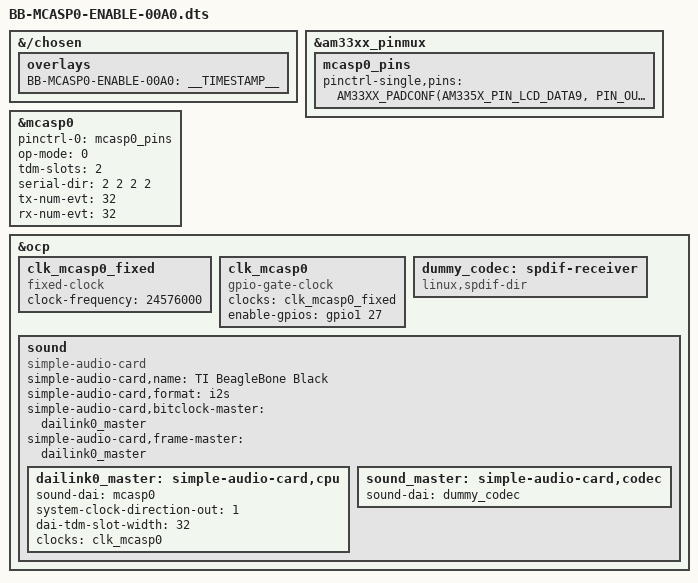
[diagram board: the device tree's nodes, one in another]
// SPDX-License-Identifier: GPL-2.0-only
/*
 * Copyright (C) 2012 Texas Instruments Incorporated - https://www.ti.com/
 */

/dts-v1/;
/plugin/;

#include <dt-bindings/pinctrl/am33xx.h>

/*
* Helper to show loaded overlays under: /proc/device-tree/chosen/overlays/
*/
&{/chosen} {
    overlays {
        BB-MCASP0-ENABLE-00A0 = __TIMESTAMP__;
    };
};

&am33xx_pinmux {
	mcasp0_pins: mcasp0_pins {
		/*

MCASP0
	AHCLKR - *Not needed, internal only*
	ACLKR
		X GPMC_BE1N - GPIO1_28 (P9)
		X MII...
		LCD_DATA12 (P8_35)
		X MCASP0_ACLKR - GPIO0_7/GPIO3_18 (P9)
	FSX
		LCD_DATA9 (P8_38)
	FSR
		X GPMC_CLK
		X MII1...
		X LCD_DATA13 (P8_33)
		X MCASP0_FSR - GPIO3_19 (P9)
	AXR0
		X GPMC...
		X MII...
		LCD_DATA10 (P8)
		X MCASP0_AXR0 - SPI1_D1 (P9)
		X MCASP0_AXR1 - GPIO3_20 (0 ohm to CLKOUT2) (P9)
	AXR1
		X GPMC_A11 (OE for HDMICLK, unusable)
		X MII...
		LCD_DATA14 (P8)
		X MCASP_AHCLKX - GPIO3_21 (P9_25)
		X MCASP0_AXR1 - GPIO3_20 (0 ohm to CLKOUT2) (P9)
	AXR2
		X MII...
		LCD_DATA11 (P8)
		X LCD_DATA12 (P8)
		X MCASP0_AHCLKR - SPI1_CS0 (P9)
		X MCASP0_ACLKR - GPIO0_7/GPIO3_18 (P9)
	AXR3
		X MII...
		LCD_DATA13 (P8)
		X LCD_DATA14 (P8)
		X MCASP0_AHCLKR - SPI1_CS0 (P9)
		X MCASP0_FSR - GPIO3_19 (P9_27)

	Can't get all 7 channels on LCD pins on P8, even w/o AHCLKR
	SPI1 used for iCE40 flashing
	Can't get all 7 channels on P9 either... Best bet is LCD on P8 + P3_19
	Note that GPIO3_19/P9_27 is BB_IRQ_ARM_TO_FPGA which we don't use on the FPGA

	LCD_DATA9 contains FSX though, we could use that instead of FSR...

	ACLKR: 	P8_35	Purple
	FSX: 	P8_38	Grey
	AXR0:	P8_36	Yellow
	AXR1:	P8_31	Orange
	AXR2:	P8_34	Blue
	AXR3:	P8_33	Green

		*/
		pinctrl-single,pins = <
			AM33XX_PADCONF(AM335X_PIN_LCD_DATA9, PIN_OUTPUT_PULLDOWN, MUX_MODE3) /* lcd_data9.mcasp0_fsx */
			AM33XX_PADCONF(AM335X_PIN_LCD_DATA10, PIN_INPUT_PULLUP, MUX_MODE3) /* lcd_data10.mcasp0_axr0 */
			AM33XX_PADCONF(AM335X_PIN_LCD_DATA11, PIN_INPUT_PULLUP, MUX_MODE4) /* lcd_data11.mcasp0_axr2 */
			AM33XX_PADCONF(AM335X_PIN_LCD_DATA12, PIN_OUTPUT_PULLDOWN, MUX_MODE3) /* lcd_data12.mcasp0_aclkr */
			AM33XX_PADCONF(AM335X_PIN_LCD_DATA13, PIN_INPUT_PULLUP, MUX_MODE4) /* lcd_data13.mcasp0_axr3 */
			AM33XX_PADCONF(AM335X_PIN_LCD_DATA14, PIN_INPUT_PULLUP, MUX_MODE3) /* lcd_data14.mcasp0_axr1 */
		>;
	};
};

&mcasp0	{
	#sound-dai-cells = <0>;
	pinctrl-names = "default";
	pinctrl-0 = <&mcasp0_pins>;
	status = "okay";
	op-mode = <0>;	/* MCASP_IIS_MODE */
	tdm-slots = <2>;
	serial-dir = <	/* 0: INACTIVE, 1: TX, 2: RX */
			2 2 2 2
		>;
	tx-num-evt = <32>;
	rx-num-evt = <32>;
};

&ocp {
	/* Use external clock as it can be divided into many more supported sample rates */
	clk_mcasp0_fixed: clk_mcasp0_fixed {
			#clock-cells = <0>;
			compatible = "fixed-clock";
			clock-frequency = <24576000>;
	};

	clk_mcasp0: clk_mcasp0 {
			#clock-cells = <0>;
			compatible = "gpio-gate-clock";
			clocks = <&clk_mcasp0_fixed>;
			enable-gpios = <&gpio1 27 0>; /* BeagleBone Black Clk enable on GPIO1_27 */
	};

	dummy_codec: spdif-receiver {
		compatible = "linux,spdif-dir";
		#sound-dai-cells = <0>;
		status="okay";
	};

	sound {
		compatible = "simple-audio-card";
		simple-audio-card,name = "TI BeagleBone Black";
		simple-audio-card,format = "i2s";\
		/* Clock and framing mastered by mcasp */
		simple-audio-card,bitclock-master = <&dailink0_master>;
		simple-audio-card,frame-master = <&dailink0_master>;

		dailink0_master: simple-audio-card,cpu {
			sound-dai = <&mcasp0>;
			system-clock-direction-out = <1>;
			dai-tdm-slot-width = <32>;
			/* Use external clk for sysclk */
			clocks = <&clk_mcasp0>;
		};

		sound_master: simple-audio-card,codec {
			sound-dai = <&dummy_codec>;
		};
	};
};
